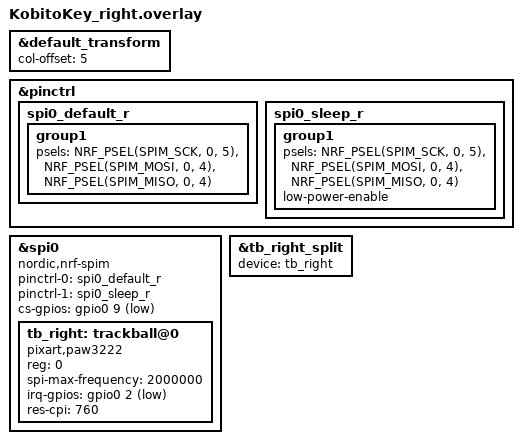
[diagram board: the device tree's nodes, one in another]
#include <zephyr/dt-bindings/pinctrl/nrf-pinctrl.h>
#include "kobitokey.dtsi"
#include <input/processors.dtsi>

/* 列オフセット */
&default_transform { col-offset = <5>; };

&pinctrl {
    spi0_default_r: spi0_default_r { group1 {
        psels = <NRF_PSEL(SPIM_SCK,  0, 5)>,
                <NRF_PSEL(SPIM_MOSI, 0, 4)>,
                <NRF_PSEL(SPIM_MISO, 0, 4)>;
    }; };
    spi0_sleep_r: spi0_sleep_r { group1 {
        psels = <NRF_PSEL(SPIM_SCK,  0, 5)>,
                <NRF_PSEL(SPIM_MOSI, 0, 4)>,
                <NRF_PSEL(SPIM_MISO, 0, 4)>;
        low-power-enable;
    }; };
};

&spi0 {
    status = "okay";
    compatible = "nordic,nrf-spim";
    pinctrl-0 = <&spi0_default_r>;
    pinctrl-1 = <&spi0_sleep_r>;
    pinctrl-names = "default", "sleep";
    cs-gpios = <&gpio0 9 GPIO_ACTIVE_LOW>;

    tb_right: trackball@0 {
        status = "okay";
        compatible = "pixart,paw3222";
        reg = <0>;
        spi-max-frequency = <2000000>;
        irq-gpios = <&gpio0 2 (GPIO_ACTIVE_LOW | GPIO_PULL_UP)>;
        res-cpi = <760>;
    };
};

/* 向きの調整は central 側 (KobitoKey_left.overlay の &tb_right_listener) で行う */
&tb_right_split {
    device = <&tb_right>;
};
